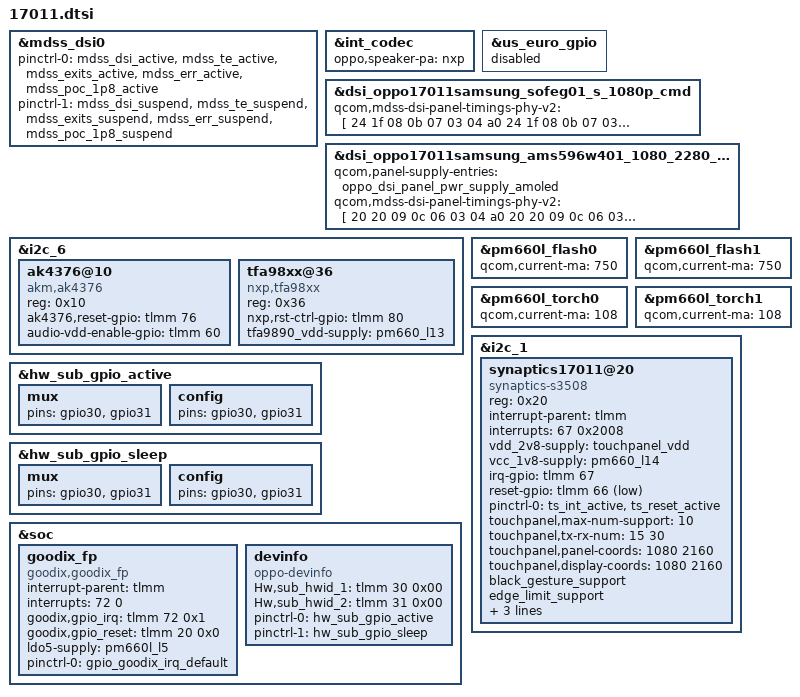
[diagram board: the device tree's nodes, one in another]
// SPDX-License-Identifier: GPL-2.0

#include "../dsi-panel-oppo17011samsung_sofeg01_1080p_cmd.dtsi"
#include "../dsi-panel-oppo17021samsung_sofeg01_1080p_cmd.dtsi"
#include "oppo-sdm660-common.dtsi"
#include "../dsi-panel-oppo17011samsung_ams596w401_1080_2280_cmd.dtsi"

&mdss_dsi0 {
	pinctrl-names = "mdss_default", "mdss_sleep";
	pinctrl-0 = <&mdss_dsi_active &mdss_te_active
			&mdss_exits_active &mdss_err_active
			&mdss_poc_1p8_active>;
	pinctrl-1 = <&mdss_dsi_suspend &mdss_te_suspend
			&mdss_exits_suspend &mdss_err_suspend
			&mdss_poc_1p8_suspend>;
};

&int_codec {
	/delete-property/ qcom,us-euro-gpios;
	oppo,speaker-pa = "nxp";
};

&us_euro_gpio {
	status = "disabled";
};

&dsi_oppo17011samsung_sofeg01_s_1080p_cmd {
	qcom,mdss-dsi-panel-timings-phy-v2 = [
		24 1f 08 0b 07 03 04 a0
		24 1f 08 0b 07 03 04 a0
		24 1f 08 0b 07 03 04 a0
		24 1f 08 0b 07 03 04 a0
		24 1f 08 0b 07 03 04 a0];
};

&dsi_oppo17011samsung_ams596w401_1080_2280_cmd {
	qcom,panel-supply-entries = <&oppo_dsi_panel_pwr_supply_amoled>;
	qcom,mdss-dsi-panel-timings-phy-v2 = [
		20 20 09 0c 06 03 04 a0
		20 20 09 0c 06 03 04 a0
		20 20 09 0c 06 03 04 a0
		20 20 09 0c 06 03 04 a0
		20 1e 09 0a 06 03 04 a0];
};

&i2c_6 {
	status = "okay";

	ak4376@10 {
		compatible = "akm,ak4376";
		reg = <0x10>;
		ak4376,reset-gpio = <&tlmm 76 0x00>;
		audio-vdd-enable-gpio = <&tlmm 60 0x00>;
		status = "okay";
	};

	tfa98xx@36 {
		compatible = "nxp,tfa98xx";
		reg = <0x36>;
		nxp,rst-ctrl-gpio = <&tlmm 80 0x00>;
		tfa9890_vdd-supply = <&pm660_l13>;
		status = "okay";
	};
};

&pm660l_flash0 {
	qcom,current-ma = <750>;
};

&pm660l_flash1 {
	qcom,current-ma = <750>;
};

&pm660l_torch0 {
	qcom,current-ma = <108>;
};

&pm660l_torch1 {
	qcom,current-ma = <108>;
};

&i2c_1 {
	status = "okay";
	synaptics17011@20 {
		compatible = "synaptics-s3508";
		reg = <0x20>;
		interrupt-parent = <&tlmm>;
		interrupts = <67 0x2008>;
		vdd_2v8-supply = <&touchpanel_vdd>;
		vcc_1v8-supply = <&pm660_l14>;
		irq-gpio = <&tlmm 67 0x2008>;
		reset-gpio = <&tlmm 66 0x1>;
		pinctrl-names = "default";
		pinctrl-0 = <&ts_int_active &ts_reset_active>;
		touchpanel,max-num-support = <10>;
		touchpanel,tx-rx-num = <15 30>;
		touchpanel,panel-coords = <1080 2160>;
		touchpanel,display-coords = <1080 2160>;
		black_gesture_support;
		edge_limit_support;
		smart_gesture_support;
		touchpanel,button-type = <4>;
		touchpanel.button-TRx = <0 0>;
	};
};

&hw_sub_gpio_active {
	mux { pins = "gpio30", "gpio31"; };
	config { pins = "gpio30", "gpio31"; };
};

&hw_sub_gpio_sleep {
	mux { pins = "gpio30", "gpio31"; };
	config { pins = "gpio30", "gpio31"; };
};

&soc {
	goodix_fp {
		compatible = "goodix,goodix_fp";
		interrupt-parent = <&tlmm>;
		interrupts = <72 0>;
		goodix,gpio_irq = <&tlmm 72 0x1>;
		goodix,gpio_reset = <&tlmm 20 0x0>;
		ldo5-supply = <&pm660l_l5>;
		pinctrl-names = "default";
		pinctrl-0 = <&gpio_goodix_irq_default>;
	};

	devinfo {
		compatible = "oppo-devinfo";
		Hw,sub_hwid_1 = <&tlmm 30 0x00>;
		Hw,sub_hwid_2 = <&tlmm 31 0x00>;
		pinctrl-names = "default", "hw_sub_gpio_sleep";
		pinctrl-0 = <&hw_sub_gpio_active>;
		pinctrl-1 = <&hw_sub_gpio_sleep>;
	};
};

#include "oppo-camera-17011.dtsi"
